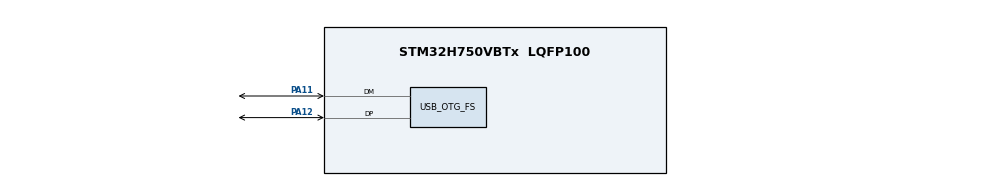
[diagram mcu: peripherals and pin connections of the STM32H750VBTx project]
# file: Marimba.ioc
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AL94.I-CUBE-USBD-COMPOSITE.1.0.3._USBD_USE_CDC_ACM=true
AL94.I-CUBE-USBD-COMPOSITE.1.0.3._USBD_USE_MSC=true
CORTEX_M7.AccessPermission_S-Cortex_Memory_Protection_Unit_Region1_Settings_S=MPU_REGION_FULL_ACCESS
CORTEX_M7.AccessPermission_S-Cortex_Memory_Protection_Unit_Region2_Settings_S=MPU_REGION_FULL_ACCESS
CORTEX_M7.AccessPermission_S-Cortex_Memory_Protection_Unit_Region3_Settings_S=MPU_REGION_FULL_ACCESS
CORTEX_M7.BaseAddress_S-Cortex_Memory_Protection_Unit_Region1_Settings_S=0x30000000
CORTEX_M7.BaseAddress_S-Cortex_Memory_Protection_Unit_Region2_Settings_S=0x20000000
CORTEX_M7.BaseAddress_S-Cortex_Memory_Protection_Unit_Region3_Settings_S=0x24000000
CORTEX_M7.CPU_DCache=Enabled
CORTEX_M7.CPU_ICache=Enabled
CORTEX_M7.Enable_S-Cortex_Memory_Protection_Unit_Region1_Settings_S=MPU_REGION_ENABLE
CORTEX_M7.Enable_S-Cortex_Memory_Protection_Unit_Region2_Settings_S=MPU_REGION_ENABLE
CORTEX_M7.Enable_S-Cortex_Memory_Protection_Unit_Region3_Settings_S=MPU_REGION_ENABLE
CORTEX_M7.IsBufferable_S-Cortex_Memory_Protection_Unit_Region1_Settings_S=MPU_ACCESS_NOT_BUFFERABLE
CORTEX_M7.IsBufferable_S-Cortex_Memory_Protection_Unit_Region2_Settings_S=MPU_ACCESS_BUFFERABLE
CORTEX_M7.IsBufferable_S-Cortex_Memory_Protection_Unit_Region3_Settings_S=MPU_ACCESS_BUFFERABLE
CORTEX_M7.IsCacheable_S-Cortex_Memory_Protection_Unit_Region1_Settings_S=MPU_ACCESS_NOT_CACHEABLE
CORTEX_M7.IsCacheable_S-Cortex_Memory_Protection_Unit_Region2_Settings_S=MPU_ACCESS_CACHEABLE
CORTEX_M7.IsCacheable_S-Cortex_Memory_Protection_Unit_Region3_Settings_S=MPU_ACCESS_CACHEABLE
CORTEX_M7.Size_S-Cortex_Memory_Protection_Unit_Region1_Settings_S=MPU_REGION_SIZE_512KB
CORTEX_M7.Size_S-Cortex_Memory_Protection_Unit_Region2_Settings_S=MPU_REGION_SIZE_128KB
CORTEX_M7.Size_S-Cortex_Memory_Protection_Unit_Region3_Settings_S=MPU_REGION_SIZE_512KB
CORTEX_M7.TypeExtField_S-Cortex_Memory_Protection_Unit_Region1_Settings_S=MPU_TEX_LEVEL1
CORTEX_M7.TypeExtField_S-Cortex_Memory_Protection_Unit_Region2_Settings_S=MPU_TEX_LEVEL1
CORTEX_M7.TypeExtField_S-Cortex_Memory_Protection_Unit_Region3_Settings_S=MPU_TEX_LEVEL1
CORTEX_M7.default_mode_Activation=1
Mcu.Family=STM32H7
Mcu.Name=STM32H750VBTx
Mcu.Package=LQFP100
NVIC.OTG_FS_EP1_IN_IRQn=true\:5\:0\:true\:false\:true\:true\:true\:true
NVIC.OTG_FS_EP1_OUT_IRQn=true\:5\:0\:true\:false\:true\:true\:true\:true
NVIC.OTG_FS_IRQn=true\:5\:0\:true\:false\:true\:true\:true\:true
NVIC.PriorityGroup=NVIC_PRIORITYGROUP_4
PA11.GPIO_Speed=GPIO_SPEED_FREQ_VERY_HIGH
PA11.Mode=Device_Only
PA11.Signal=USB_OTG_FS_DM
PA12.GPIO_Speed=GPIO_SPEED_FREQ_VERY_HIGH
PA12.Mode=Device_Only
PA12.Signal=USB_OTG_FS_DP
PA13\ (JTMS/SWDIO).Mode=Serial_Wire
PA13\ (JTMS/SWDIO).Signal=DEBUG_JTMS-SWDIO
PA14\ (JTCK/SWCLK).Mode=Serial_Wire
PA14\ (JTCK/SWCLK).Signal=DEBUG_JTCK-SWCLK
PH0-OSC_IN\ (PH0).Mode=HSE-External-Oscillator
PH0-OSC_IN\ (PH0).Signal=RCC_OSC_IN
PH1-OSC_OUT\ (PH1).Mode=HSE-External-Oscillator
PH1-OSC_OUT\ (PH1).Signal=RCC_OSC_OUT
ProjectManager.HeapSize=0x2000
ProjectManager.StackSize=0x6000
ProjectManager.TargetToolchain=EWARM V8.50
RCC.ADCFreq_Value=80000000
RCC.APB1Freq_Value=100000000
RCC.APB2Freq_Value=100000000
RCC.APB3Freq_Value=100000000
RCC.APB4Freq_Value=100000000
RCC.CortexFreq_Value=400000000
RCC.D1PPRE=RCC_APB3_DIV2
RCC.D2PPRE1=RCC_APB1_DIV2
RCC.D2PPRE2=RCC_APB2_DIV2
RCC.D3PPRE=RCC_APB4_DIV2
RCC.DIVM1=1
RCC.DIVM2=1
RCC.DIVN1=100
RCC.DIVN2=20
RCC.DIVQ1=4
RCC.HCLKFreq_Value=200000000
RCC.HPRE=RCC_HCLK_DIV2
RCC.HSE_VALUE=8000000
RCC.PLL2FRACN=0
RCC.PLLFRACN=0
RCC.PLLSourceVirtual=RCC_PLLSOURCE_HSE
RCC.SYSCLKFreq_VALUE=400000000
RCC.SYSCLKSource=RCC_SYSCLKSOURCE_PLLCLK
RCC.USBCLockSelection=RCC_USBCLKSOURCE_HSI48
RCC.USBFreq_Value=48000000
STMicroelectronics.X-CUBE-AZRTOS-H7.3.2.0_IsAnAzureRtosMw=true
USB_DEVICE.APP_RX_DATA_SIZE-CDC_FS=512
USB_DEVICE.APP_TX_DATA_SIZE-CDC_FS=512
USB_DEVICE.CLASS_NAME_FS=CDC
USB_DEVICE.VirtualMode-CDC_FS=Cdc
USB_DEVICE.VirtualModeFS=Cdc_FS
USB_OTG_FS.VirtualMode=Device_Only
VP_MEMORYMAP_VS_MEMORYMAP.Mode=CurAppReg
VP_USB_DEVICE_VS_USB_DEVICE_CDC_FS.Mode=CDC_FS
board=custom

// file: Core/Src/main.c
/* USER CODE BEGIN Header */
/**
  ******************************************************************************
  * @file           : main.c
  * @brief          : Main program body
  ******************************************************************************
  * @attention
  *
  * Copyright (c) 2024 STMicroelectronics.
  * All rights reserved.
  *
  * This software is licensed under terms that can be found in the LICENSE file
  * in the root directory of this software component.
  * If no LICENSE file comes with this software, it is provided AS-IS.
  *
  ******************************************************************************
  */
/* USER CODE END Header */
#include "main.h"
#include "memorymap.h"
#include "usb_device.h"
#include "gpio.h"

/* USER CODE BEGIN Includes */
#include "usbd_midi_if.h"
/* USER CODE END Includes */

void SystemClock_Config(void);
static void MPU_Config(void);

/* USER CODE BEGIN 0 */
uint8_t send = 0;
/* USER CODE END 0 */

int main(void)
{

  /* MPU Configuration--------------------------------------------------------*/
  MPU_Config();

  /* Enable the CPU Cache */

  /* Enable I-Cache---------------------------------------------------------*/
  SCB_EnableICache();

  /* Enable D-Cache---------------------------------------------------------*/
  SCB_EnableDCache();

  /* MCU Configuration--------------------------------------------------------*/

  /* Reset of all peripherals, Initializes the Flash interface and the Systick. */
  HAL_Init();

  /* Configure the system clock */
  SystemClock_Config();

  /* Initialize all configured peripherals */
  MX_GPIO_Init();
  MX_USB_DEVICE_Init();

  /* Infinite loop */
  /* USER CODE BEGIN WHILE */
  while (1)
  {
    if(send)
    USBMIDI_send(0x0BB90012);
    USBMIDI_polling();
    /* USER CODE END WHILE */

  }
}

void SystemClock_Config(void)
{
  RCC_OscInitTypeDef RCC_OscInitStruct = {0};
  RCC_ClkInitTypeDef RCC_ClkInitStruct = {0};

  /** Supply configuration update enable
  */
  HAL_PWREx_ConfigSupply(PWR_LDO_SUPPLY);

  /** Configure the main internal regulator output voltage
  */
  __HAL_PWR_VOLTAGESCALING_CONFIG(PWR_REGULATOR_VOLTAGE_SCALE1);

  while(!__HAL_PWR_GET_FLAG(PWR_FLAG_VOSRDY)) {}

  /** Initializes the RCC Oscillators according to the specified parameters
  * in the RCC_OscInitTypeDef structure.
  */
  RCC_OscInitStruct.OscillatorType = RCC_OSCILLATORTYPE_HSI48|RCC_OSCILLATORTYPE_HSE;
  RCC_OscInitStruct.HSEState = RCC_HSE_ON;
  RCC_OscInitStruct.HSI48State = RCC_HSI48_ON;
  RCC_OscInitStruct.PLL.PLLState = RCC_PLL_ON;
  RCC_OscInitStruct.PLL.PLLSource = RCC_PLLSOURCE_HSE;
  RCC_OscInitStruct.PLL.PLLM = 1;
  RCC_OscInitStruct.PLL.PLLN = 100;
  RCC_OscInitStruct.PLL.PLLP = 2;
  RCC_OscInitStruct.PLL.PLLQ = 4;
  RCC_OscInitStruct.PLL.PLLR = 2;
  RCC_OscInitStruct.PLL.PLLRGE = RCC_PLL1VCIRANGE_3;
  RCC_OscInitStruct.PLL.PLLVCOSEL = RCC_PLL1VCOWIDE;
  RCC_OscInitStruct.PLL.PLLFRACN = 0;
  if (HAL_RCC_OscConfig(&RCC_OscInitStruct) != HAL_OK)
  {
    Error_Handler();
  }

  /** Initializes the CPU, AHB and APB buses clocks
  */
  RCC_ClkInitStruct.ClockType = RCC_CLOCKTYPE_HCLK|RCC_CLOCKTYPE_SYSCLK
                              |RCC_CLOCKTYPE_PCLK1|RCC_CLOCKTYPE_PCLK2
                              |RCC_CLOCKTYPE_D3PCLK1|RCC_CLOCKTYPE_D1PCLK1;
  RCC_ClkInitStruct.SYSCLKSource = RCC_SYSCLKSOURCE_PLLCLK;
  RCC_ClkInitStruct.SYSCLKDivider = RCC_SYSCLK_DIV1;
  RCC_ClkInitStruct.AHBCLKDivider = RCC_HCLK_DIV2;
  RCC_ClkInitStruct.APB3CLKDivider = RCC_APB3_DIV2;
  RCC_ClkInitStruct.APB1CLKDivider = RCC_APB1_DIV2;
  RCC_ClkInitStruct.APB2CLKDivider = RCC_APB2_DIV2;
  RCC_ClkInitStruct.APB4CLKDivider = RCC_APB4_DIV2;

  if (HAL_RCC_ClockConfig(&RCC_ClkInitStruct, FLASH_LATENCY_2) != HAL_OK)
  {
    Error_Handler();
  }
}

 /* MPU Configuration */

void MPU_Config(void)
{
  MPU_Region_InitTypeDef MPU_InitStruct = {0};

  /* Disables the MPU */
  HAL_MPU_Disable();

  /** Initializes and configures the Region and the memory to be protected
  */
  MPU_InitStruct.Enable = MPU_REGION_ENABLE;
  MPU_InitStruct.Number = MPU_REGION_NUMBER0;
  MPU_InitStruct.BaseAddress = 0x0;
  MPU_InitStruct.Size = MPU_REGION_SIZE_4GB;
  MPU_InitStruct.SubRegionDisable = 0x87;
  MPU_InitStruct.TypeExtField = MPU_TEX_LEVEL0;
  MPU_InitStruct.AccessPermission = MPU_REGION_NO_ACCESS;
  MPU_InitStruct.DisableExec = MPU_INSTRUCTION_ACCESS_DISABLE;
  MPU_InitStruct.IsShareable = MPU_ACCESS_SHAREABLE;
  MPU_InitStruct.IsCacheable = MPU_ACCESS_NOT_CACHEABLE;
  MPU_InitStruct.IsBufferable = MPU_ACCESS_NOT_BUFFERABLE;

  HAL_MPU_ConfigRegion(&MPU_InitStruct);

  /** Initializes and configures the Region and the memory to be protected
  */
  MPU_InitStruct.Number = MPU_REGION_NUMBER1;
  MPU_InitStruct.BaseAddress = 0x30000000;
  MPU_InitStruct.Size = MPU_REGION_SIZE_512KB;
  MPU_InitStruct.SubRegionDisable = 0x0;
  MPU_InitStruct.TypeExtField = MPU_TEX_LEVEL1;
  MPU_InitStruct.AccessPermission = MPU_REGION_FULL_ACCESS;
  MPU_InitStruct.DisableExec = MPU_INSTRUCTION_ACCESS_ENABLE;
  MPU_InitStruct.IsShareable = MPU_ACCESS_NOT_SHAREABLE;

  HAL_MPU_ConfigRegion(&MPU_InitStruct);

  /** Initializes and configures the Region and the memory to be protected
  */
  MPU_InitStruct.Number = MPU_REGION_NUMBER2;
  MPU_InitStruct.BaseAddress = 0x20000000;
  MPU_InitStruct.Size = MPU_REGION_SIZE_128KB;
  MPU_InitStruct.IsCacheable = MPU_ACCESS_CACHEABLE;
  MPU_InitStruct.IsBufferable = MPU_ACCESS_BUFFERABLE;

  HAL_MPU_ConfigRegion(&MPU_InitStruct);

  /** Initializes and configures the Region and the memory to be protected
  */
  MPU_InitStruct.Number = MPU_REGION_NUMBER3;
  MPU_InitStruct.BaseAddress = 0x24000000;
  MPU_InitStruct.Size = MPU_REGION_SIZE_512KB;

  HAL_MPU_ConfigRegion(&MPU_InitStruct);
  /* Enables the MPU */
  HAL_MPU_Enable(MPU_PRIVILEGED_DEFAULT);

}

void Error_Handler(void)
{
  __disable_irq();
  while (1)
  {
  }
}
